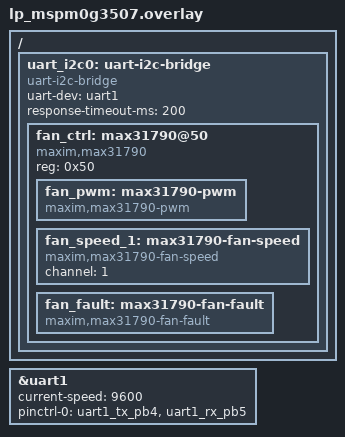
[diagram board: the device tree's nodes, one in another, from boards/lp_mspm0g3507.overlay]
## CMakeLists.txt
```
# SPDX-License-Identifier: Apache-2.0

cmake_minimum_required(VERSION 3.20.0)
find_package(Zephyr REQUIRED HINTS $ENV{ZEPHYR_BASE})
project(max31790_fan)

target_sources(app PRIVATE src/main.c)
```

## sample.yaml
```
sample:
  name: MAX31790 Fan Controller
  description: >
    Demonstrates MAX31790 6-channel PWM fan controller via the Zephyr MFD,
    PWM and sensor drivers. Reads fan speed (RPM) and fault status, and
    sets fan duty cycle over PWM. Supports both direct I2C and UART-to-I2C
    bridge (MSPM0G) topologies.
common:
  tags:
    - drivers
    - fan
    - pwm
    - sensor
  filter: dt_compat_enabled("maxim,max31790")
  depends_on: i2c
tests:
  sample.drivers.max31790_fan:
    build_only: true
    platform_allow:
      - lp_mspm0g3507
      - lp_mspm0g3519
    tags: fan pwm sensor i2c
    integration_platforms:
      - lp_mspm0g3507
```

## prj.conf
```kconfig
CONFIG_MFD=y
CONFIG_MFD_MAX31790=y
CONFIG_PWM=y
CONFIG_PWM_MAX31790=y
CONFIG_SENSOR=y
CONFIG_MAX31790_FAN_SPEED=y
CONFIG_MAX31790_FAN_FAULT=y
CONFIG_I2C=y
CONFIG_UART_INTERRUPT_DRIVEN=y
CONFIG_GPIO=y
CONFIG_LOG=y
CONFIG_PWM_INIT_PRIORITY=85
```

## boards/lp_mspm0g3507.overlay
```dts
/*
 * SPDX-License-Identifier: Apache-2.0
 *
 * MAX31790 accessed via the UART-to-I2C bridge driver.
 * UART1 (PB4/PB5) links to the fixed-function MSPM0G bridge MCU.
 */

&uart1 {
	status = "okay";
	current-speed = <9600>;
	pinctrl-0 = <&uart1_tx_pb4 &uart1_rx_pb5>;
	pinctrl-names = "default";
};

/ {
	uart_i2c0: uart-i2c-bridge {
		compatible = "uart-i2c-bridge";
		uart-dev = <&uart1>;
		response-timeout-ms = <200>;
		#address-cells = <1>;
		#size-cells = <0>;

		fan_ctrl: max31790@50 {
			compatible = "maxim,max31790";
			reg = <0x50>;

			fan_pwm: max31790-pwm {
				compatible = "maxim,max31790-pwm";
				#pwm-cells = <2>;
			};

			fan_speed_1: max31790-fan-speed {
				compatible = "maxim,max31790-fan-speed";
				channel = <1>;
			};

			fan_fault: max31790-fan-fault {
				compatible = "maxim,max31790-fan-fault";
			};
		};
	};
};
```

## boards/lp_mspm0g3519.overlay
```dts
/*
 * SPDX-License-Identifier: Apache-2.0
 *
 * MAX31790 accessed via the UART-to-I2C bridge driver.
 * UART1 (PB4/PB5) connects to the fixed-function MSPM0G bridge MCU
 * running uart_i2c_bridge firmware (SHared_i2c protocol), which
 * translates UART frames to I2C and drives the MAX31790 fan controller.
 *
 * Wiring:
 *   lp_mspm0g3519 PB4 (UART1 TX) → bridge MCU UART RX (PA11)
 *   lp_mspm0g3519 PB5 (UART1 RX) → bridge MCU UART TX (PA10)
 *   GND ↔ GND
 */

&uart1 {
	status = "okay";
	current-speed = <9600>;
	pinctrl-0 = <&uart1_tx_pb4 &uart1_rx_pb5>;
	pinctrl-names = "default";
};

/ {
	uart_i2c0: uart-i2c-bridge {
		compatible = "uart-i2c-bridge";
		uart-dev = <&uart1>;
		response-timeout-ms = <200>;
		#address-cells = <1>;
		#size-cells = <0>;

		fan_ctrl: max31790@50 {
			compatible = "maxim,max31790";
			reg = <0x50>;

			fan_pwm: max31790-pwm {
				compatible = "maxim,max31790-pwm";
				#pwm-cells = <2>;
			};

			fan_speed_1: max31790-fan-speed {
				compatible = "maxim,max31790-fan-speed";
				channel = <1>;
			};

			fan_fault: max31790-fan-fault {
				compatible = "maxim,max31790-fan-fault";
			};
		};
	};
};
```

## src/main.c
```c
/*
 * Copyright (c) 2025
 * SPDX-License-Identifier: Apache-2.0
 *
 * MAX31790 fan controller sample — PWM set, RPM read, fault monitor.
 *
 * Works with any I2C topology exposing a maxim,max31790 node, including
 * the uart-i2c-bridge driver on MSPM0G.
 *
 * PC testing (lp_mspm0g3519):
 *   Console is disabled; uart0 carries the bridge protocol.
 *   Run bridge_test.py on the PC to validate packets and respond to reads.
 *
 * LED feedback:
 *   Blue  (LED0) blinks 1 Hz = running normally
 *   Red   (LED1) solid on    = device init failed
 */

#include <zephyr/kernel.h>
#include <zephyr/device.h>
#include <zephyr/drivers/gpio.h>
#include <zephyr/drivers/pwm.h>
#include <zephyr/drivers/sensor.h>
#include <zephyr/drivers/sensor/max31790.h>
#include <zephyr/logging/log.h>

LOG_MODULE_REGISTER(max31790_fan, LOG_LEVEL_INF);

#define FAN_PWM_NODE   DT_NODELABEL(fan_pwm)
#define FAN_SPEED_NODE DT_NODELABEL(fan_speed_1)
#define FAN_FAULT_NODE DT_NODELABEL(fan_fault)

#define FAN_PERIOD_NS  40000U   /* 25 kHz */
#define FAN_CHANNEL    1U
#define FAN_DUTY_PCT   50U

static const struct gpio_dt_spec led_run = GPIO_DT_SPEC_GET(DT_ALIAS(led0), gpios);

#if DT_HAS_ALIAS(led1)
static const struct gpio_dt_spec led_fail = GPIO_DT_SPEC_GET(DT_ALIAS(led1), gpios);
#define LED_FAIL_SET(v) gpio_pin_set_dt(&led_fail, v)
#define LED_FAIL_INIT() gpio_pin_configure_dt(&led_fail, GPIO_OUTPUT_INACTIVE)
#else
/* Board has only one LED — use it for run indicator; failures visible via log */
#define LED_FAIL_SET(v) (void)(v)
#define LED_FAIL_INIT() do {} while (0)
#endif

int main(void)
{
	const struct device *fan_pwm   = DEVICE_DT_GET(FAN_PWM_NODE);
	const struct device *fan_speed = DEVICE_DT_GET(FAN_SPEED_NODE);
	const struct device *fan_fault = DEVICE_DT_GET(FAN_FAULT_NODE);

	gpio_pin_configure_dt(&led_run, GPIO_OUTPUT_INACTIVE);
	LED_FAIL_INIT();

	if (!device_is_ready(fan_pwm) ||
	    !device_is_ready(fan_speed) ||
	    !device_is_ready(fan_fault)) {
		LED_FAIL_SET(1);
		LOG_ERR("MAX31790 device(s) not ready");
		return -ENODEV;
	}

	LOG_INF("MAX31790 ready via UART-I2C bridge");

	uint32_t pulse_ns = FAN_PERIOD_NS * FAN_DUTY_PCT / 100U;
	int ret = pwm_set(fan_pwm, FAN_CHANNEL, FAN_PERIOD_NS, pulse_ns, 0);

	if (ret) {
		LED_FAIL_SET(1);
		LOG_ERR("PWM set failed: %d", ret);
		return ret;
	}

	LOG_INF("Fan ch%u: %u%% duty", FAN_CHANNEL, FAN_DUTY_PCT);

	while (1) {
		gpio_pin_toggle_dt(&led_run);

		struct sensor_value rpm, fault;

		if (sensor_sample_fetch(fan_speed) == 0) {
			sensor_channel_get(fan_speed, SENSOR_CHAN_RPM, &rpm);
			LOG_INF("Fan %u: %d RPM", FAN_CHANNEL, rpm.val1);
		}

		if (sensor_sample_fetch(fan_fault) == 0) {
			sensor_channel_get(fan_fault,
					   SENSOR_CHAN_MAX31790_FAN_FAULT,
					   &fault);
			if (fault.val1) {
				LOG_WRN("Fault: 0x%02x", fault.val1);
			}
		}

		k_sleep(K_SECONDS(2));
	}

	return 0;
}
```
